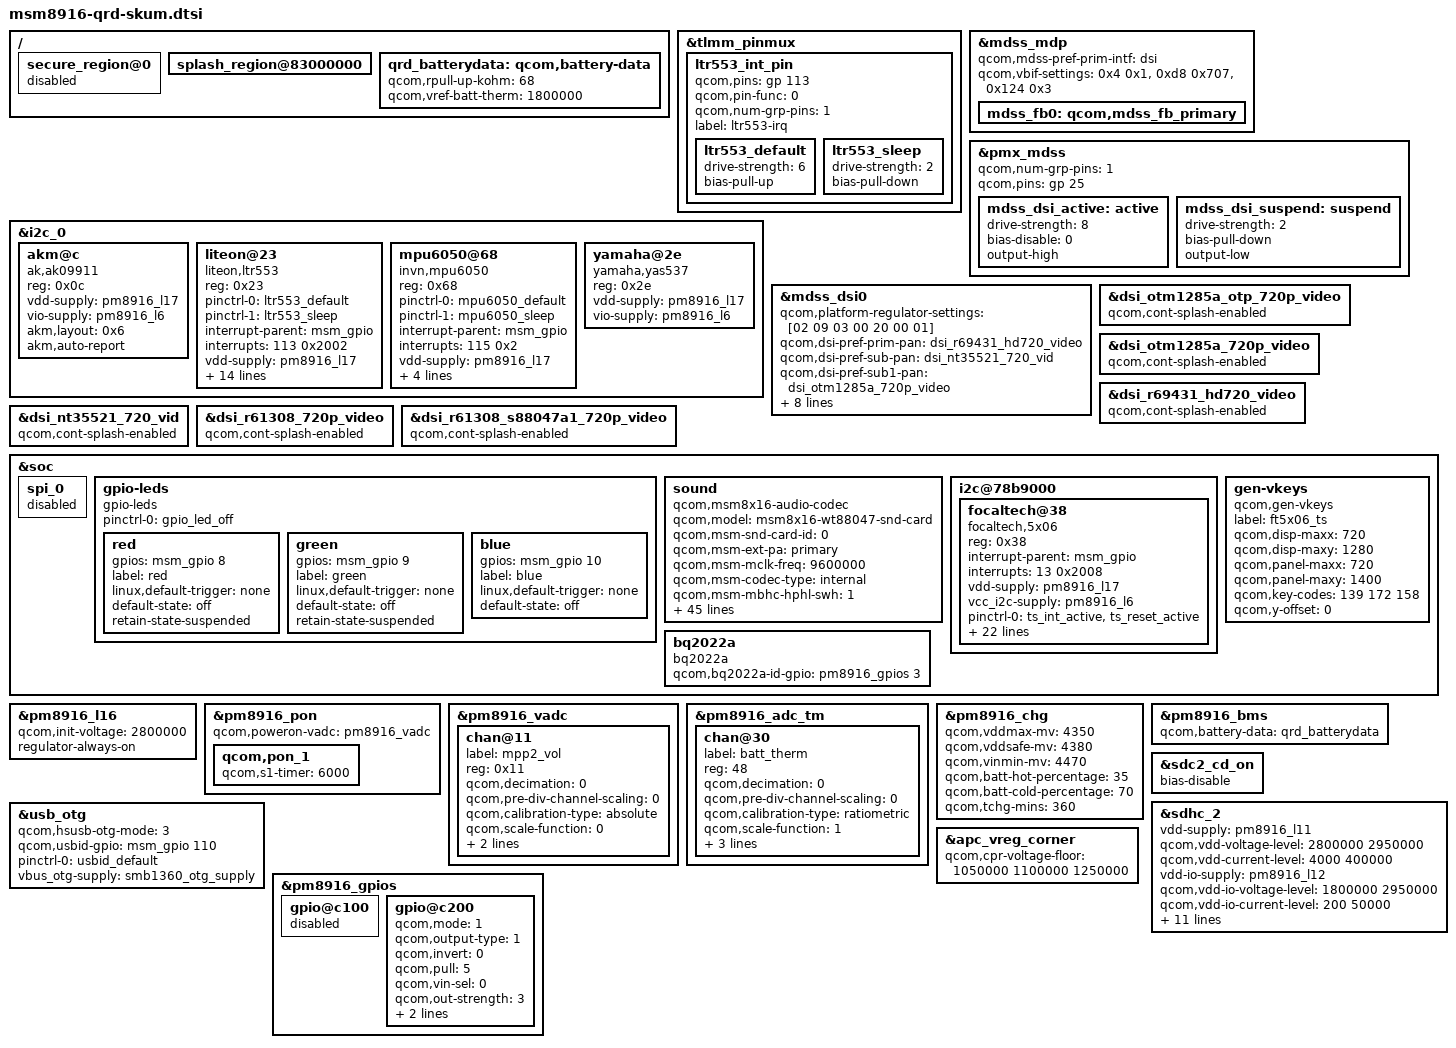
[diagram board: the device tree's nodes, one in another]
/* Copyright (c) 2014, The Linux Foundation. All rights reserved.
 *
 * This program is free software; you can redistribute it and/or modify
 * it under the terms of the GNU General Public License version 2 and
 * only version 2 as published by the Free Software Foundation.
 *
 * This program is distributed in the hope that it will be useful,
 * but WITHOUT ANY WARRANTY; without even the implied warranty of
 * MERCHANTABILITY or FITNESS FOR A PARTICULAR PURPOSE.  See the
 * GNU General Public License for more details.
 */

#include "msm8916-qrd.dtsi"
#include "msm8916-camera-sensor-qrd-skum.dtsi"
#include "dsi-panel-r69431-hd720-video.dtsi"
#include "dsi-panel-nt35521-720p-video.dtsi"
#include "dsi-panel-otm1285a-720p-video.dtsi"
#include "dsi-panel-r61308-720p-video.dtsi"
#include "dsi-panel-otm1285a-otp-720p-video.dtsi"
#include "dsi-panel-r61308-s88047a1-720p-video.dtsi"


/ {
        secure_region@0 {
	           status = "disabled";
	};
        splash_region@83000000 { /* Give this region to mdss_fb0 */
               /* status = "disabled"; */
	};
};

&tlmm_pinmux {
	ltr553_int_pin {
		qcom,pins = <&gp 113>;
		qcom,pin-func = <0>;
		qcom,num-grp-pins = <1>;
		label = "ltr553-irq";
		ltr553_default: ltr553_default {
			drive-strength = <6>;
			bias-pull-up;
		};
		ltr553_sleep: ltr553_sleep {
			drive-strength = <2>;
			bias-pull-down;
		};
	};
};

&i2c_0 { /* BLSP1 QUP2 */
	akm@c { /* Magnetic field sensor */
		compatible = "ak,ak09911";
		reg = <0x0c>;
		vdd-supply = <&pm8916_l17>;
		vio-supply = <&pm8916_l6>;
		akm,layout = <0x6>;
		akm,auto-report;
	};
	
	liteon@23 {
		compatible = "liteon,ltr553";
		reg = <0x23>;
		pinctrl-names = "default","sleep";
		pinctrl-0 = <&ltr553_default>;
		pinctrl-1 = <&ltr553_sleep>;
		interrupt-parent = <&msm_gpio>;
		interrupts = <113 0x2002>;
		vdd-supply = <&pm8916_l17>;
		vio-supply = <&pm8916_l6>;
		liteon,irq-gpio = <&msm_gpio 113 0x2002>;
		liteon,ps-threshold = <250>;
		liteon,ps-hysteresis-threshold = <150>;
		liteon,als-polling-time = <200>;
		liteon,als-ps-persist = <0>;
		liteon,ps-led = <0x7f>;
		liteon,ps-pulses = <4>;
		liteon,wakeup-threshold = <4>;
		liteon,als-integration-time = <0>;
		liteon,als-equation-0 = <1 1 7743 1059 600 1>;
		liteon,als-equation-1 = <4 1 2785 696 240 (-1)>;
		liteon,als-equation-2 = <0 0 5926 1300 44 1>;
		liteon,als-equation-3 = <0 0 0 0 1 1>;
	};

	mpu6050@68 {
		compatible = "invn,mpu6050";
		reg = <0x68>;
		pinctrl-names = "mpu_default","mpu_sleep";
		pinctrl-0 = <&mpu6050_default>;
		pinctrl-1 = <&mpu6050_sleep>;
		interrupt-parent = <&msm_gpio>;
		interrupts = <115 0x2>;
		vdd-supply = <&pm8916_l17>;	
		vlogic-supply = <&pm8916_l16>;
		vi2c-supply = <&pm8916_l6>;
		invn,gpio-int = <&msm_gpio 115 0x2>;
		invn,place = "Portrait Up Back Side";
	};

	yamaha@2e {
		compatible = "yamaha,yas537";
		reg = <0x2e>;
		vdd-supply = <&pm8916_l17>;
		vio-supply = <&pm8916_l6>;
	};
		
};

&mdss_mdp {
	qcom,mdss-pref-prim-intf = "dsi";
	qcom,vbif-settings = <0x4 0x1>, <0xd8 0x707>, <0x124 0x3>;

	mdss_fb0: qcom,mdss_fb_primary {
		/* Ketut P. Kumajaya: For old bootloader, old splash image */
		/* Both recovery and bootanimation framebuffer need this */
		/* qcom,memblock-reserve = <0x83200000 0xfa0000>;
		qcom,mdss-fb-splash-logo-enabled; */
	};
};

&pmx_mdss {
	qcom,num-grp-pins = <1>;
	qcom,pins = <&gp 25>;
	mdss_dsi_active: active {
		drive-strength = <8>; /* 8 mA */
		bias-disable = <0>; /* no pull */
		output-high;
	};
	mdss_dsi_suspend: suspend {
		drive-strength = <2>; /* 2 mA */
		bias-pull-down; /* pull down */
		output-low;
	};
};


&mdss_dsi0 {
	qcom,platform-regulator-settings = [02 09 03 00 20 00 01];
	qcom,dsi-pref-prim-pan = <&dsi_r69431_hd720_video>;
	qcom,dsi-pref-sub-pan = <&dsi_nt35521_720_vid>;
	qcom,dsi-pref-sub1-pan = <&dsi_otm1285a_720p_video>;
	qcom,dsi-pref-sub2-pan = <&dsi_r61308_720p_video>;
	qcom,dsi-pref-sub3-pan = <&dsi_otm1285a_otp_720p_video>;
	qcom,dsi-pref-sub4-pan = <&dsi_r61308_s88047a1_720p_video>;
	pinctrl-names = "mdss_default", "mdss_sleep";
	pinctrl-0 = <&mdss_dsi_active>;
	pinctrl-1 = <&mdss_dsi_suspend>;

	qcom,platform-reset-gpio = <&msm_gpio 25 0>;
};

&dsi_otm1285a_otp_720p_video {
    qcom,cont-splash-enabled;
};

&dsi_otm1285a_720p_video {
    qcom,cont-splash-enabled;
};

&dsi_r69431_hd720_video {
    qcom,cont-splash-enabled;
};

&dsi_nt35521_720_vid {
    qcom,cont-splash-enabled;
};

&dsi_r61308_720p_video {
    qcom,cont-splash-enabled;
};

&dsi_r61308_s88047a1_720p_video {
    qcom,cont-splash-enabled;
};



&soc {
	spi_0 {
		status = "disabled";
	};

	gpio-leds {
		compatible = "gpio-leds";
		status = "okay";
		pinctrl-names = "default";
		pinctrl-0 = <&gpio_led_off>;

		red {
			gpios = <&msm_gpio 8 0>;
			label = "red";
			linux,default-trigger = "none";
			default-state = "off";
			retain-state-suspended;
		};

		green {
			gpios = <&msm_gpio 9 0>;
			label = "green";
			linux,default-trigger = "none";
			default-state = "off";
			retain-state-suspended;
		};

		blue {
			gpios = <&msm_gpio 10 0>;
			label = "blue";
			linux,default-trigger = "none";
			default-state = "off";
		};
	};

	sound {
		compatible = "qcom,msm8x16-audio-codec";
		qcom,model = "msm8x16-wt88047-snd-card";
		qcom,msm-snd-card-id = <0>;
		qcom,msm-ext-pa = "primary";
		qcom,msm-mclk-freq = <9600000>;
		qcom,msm-codec-type = "internal";
		qcom,msm-mbhc-hphl-swh = <1>;
		qcom,msm-mbhc-gnd-swh = <0>;
		qcom,msm-hs-micbias-type = "internal";
		qcom,audio-routing =
			"RX_BIAS", "MCLK",
			"SPK_RX_BIAS", "MCLK",
			"INT_LDO_H", "MCLK",
			"MIC BIAS External", "Handset Mic",
			"MIC BIAS Internal2", "Headset Mic",
			"MIC BIAS External", "Secondary Mic",
			"AMIC1", "MIC BIAS External",
			"AMIC2", "MIC BIAS Internal2",
			"AMIC3", "MIC BIAS External";
		pinctrl-names = "cdc_lines_act",
				"cdc_lines_sus";
		pinctrl-0 = <&cdc_pdm_lines_act>;
		pinctrl-1 = <&cdc_pdm_lines_sus>;
		asoc-platform = <&pcm0>, <&pcm1>, <&voip>, <&voice>,
				<&loopback>, <&compress>, <&hostless>,
				<&afe>, <&lsm>, <&routing>, <&lpa>;
		asoc-platform-names = "msm-pcm-dsp.0", "msm-pcm-dsp.1",
				"msm-voip-dsp", "msm-pcm-voice", "msm-pcm-loopback",
				"msm-compress-dsp", "msm-pcm-hostless", "msm-pcm-afe",
				"msm-lsm-client", "msm-pcm-routing", "msm-pcm-lpa";
		asoc-cpu = <&dai_pri_auxpcm>, <&dai_hdmi>,
				<&dai_mi2s0>, <&dai_mi2s1>, <&dai_mi2s2>, <&dai_mi2s3>,
				<&sb_0_rx>, <&sb_0_tx>, <&sb_1_rx>, <&sb_1_tx>,
				<&sb_3_rx>, <&sb_3_tx>, <&sb_4_rx>, <&sb_4_tx>,
				<&bt_sco_rx>, <&bt_sco_tx>, <&bt_a2dp_rx>,
				<&int_fm_rx>, <&int_fm_tx>,
				<&afe_pcm_rx>, <&afe_pcm_tx>, <&afe_proxy_rx>, <&afe_proxy_tx>,
				<&incall_record_rx>, <&incall_record_tx>, <&incall_music_rx>,
				<&incall_music_2_rx>;
		asoc-cpu-names = "msm-dai-q6-auxpcm.1", "msm-dai-q6-hdmi.8",
				"msm-dai-q6-mi2s.0", "msm-dai-q6-mi2s.1",
				"msm-dai-q6-mi2s.2", "msm-dai-q6-mi2s.3",
				"msm-dai-q6-dev.16384", "msm-dai-q6-dev.16385",
				"msm-dai-q6-dev.16386", "msm-dai-q6-dev.16387",
				"msm-dai-q6-dev.16390", "msm-dai-q6-dev.16391",
				"msm-dai-q6-dev.16392", "msm-dai-q6-dev.16393",
				"msm-dai-q6-dev.12288", "msm-dai-q6-dev.12289",
				"msm-dai-q6-dev.12290", "msm-dai-q6-dev.12292",
				"msm-dai-q6-dev.12293",	"msm-dai-q6-dev.224",
				"msm-dai-q6-dev.225", "msm-dai-q6-dev.241",
				"msm-dai-q6-dev.240", "msm-dai-q6-dev.32771",
				"msm-dai-q6-dev.32772", "msm-dai-q6-dev.32773",
				"msm-dai-q6-dev.32770";
		asoc-codec = <&stub_codec>, <&pm8916_tombak_dig>;
		asoc-codec-names = "msm-stub-codec.1", "tombak_codec";
	};

	i2c@78b9000 { /* BLSP1 QUP5 */
		focaltech@38 {
			compatible = "focaltech,5x06";
			reg = <0x38>;
			interrupt-parent = <&msm_gpio>;
			interrupts = <13 0x2008>;
			vdd-supply = <&pm8916_l17>;
			vcc_i2c-supply = <&pm8916_l6>;
			/* pins used by touchscreen */
			pinctrl-names = "pmx_ts_active","pmx_ts_suspend";
			pinctrl-0 = <&ts_int_active &ts_reset_active>;
			pinctrl-1 = <&ts_int_suspend &ts_reset_suspend>;
			focaltech,name = "ft6436";
			focaltech,family-id = <0x36>;
			focaltech,reset-gpio = <&msm_gpio 12 0x0>;
			focaltech,irq-gpio = <&msm_gpio 13 0x2008>;
			focaltech,display-coords = <0 0 720 1280>;
			focaltech,panel-coords = <0 0 720 1280>;
			focaltech,button-map= <139 102 158>;
			focaltech,no-force-update;
			focaltech,i2c-pull-up;
			focaltech,group-id = <1>;
			focaltech,hard-reset-delay-ms = <20>;
			focaltech,soft-reset-delay-ms = <200>;
			focaltech,num-max-touches = <5>;
			focaltech,fw-delay-aa-ms = <30>;
			focaltech,fw-delay-55-ms = <30>;
			focaltech,fw-upgrade-id1 = <0x79>;
			focaltech,fw-upgrade-id2 = <0x18>;
			focaltech,fw-delay-readid-ms = <10>;
			focaltech,fw-delay-era-flsh-ms = <2000>;
			focaltech,fw-auto-cal;
			focaltech,ignore-id-check;
		};
	};


	gen-vkeys {
		compatible = "qcom,gen-vkeys";
		label = "ft5x06_ts";
		qcom,disp-maxx = <720>;
		qcom,disp-maxy = <1280>;
		qcom,panel-maxx = <720>;
		qcom,panel-maxy = <1400>;
		qcom,key-codes = <139 172 158>;
		qcom,y-offset = <0>;
	};

       bq2022a {
		compatible = "bq2022a";
		qcom,bq2022a-id-gpio = <&pm8916_gpios 3 0>;
		status= "okay";
	};

};

&pm8916_l16 {
	qcom,init-voltage = <2800000>;
	regulator-always-on;
};

&pm8916_pon {
	qcom,poweron-vadc = <&pm8916_vadc>;

	qcom,pon_1 {
		qcom,s1-timer = <6000>;
	};
};

&pm8916_vadc {
	chan@11 {
		label = "mpp2_vol";
		reg = <0x11>;
		qcom,decimation = <0>;
		qcom,pre-div-channel-scaling = <0>;
		qcom,calibration-type = "absolute";
		qcom,scale-function = <0>;
		qcom,hw-settle-time = <0>;
		qcom,fast-avg-setup = <0>;
	};
};

&pm8916_adc_tm {
	chan@30 {
		label = "batt_therm";
		reg = <48>;
		qcom,decimation = <0>;
		qcom,pre-div-channel-scaling = <0>;
		qcom,calibration-type = "ratiometric";
		qcom,scale-function = <1>;
		qcom,hw-settle-time = <11>;
		qcom,fast-avg-setup = <3>;
		qcom,btm-channel-number = <72>;
	};
};

&pm8916_chg {
	qcom,vddmax-mv = <4350>;
	qcom,vddsafe-mv = <4380>;
	qcom,vinmin-mv = <4470>;
	qcom,batt-hot-percentage = <35>;
	qcom,batt-cold-percentage = <70>;
	qcom,tchg-mins = <360>;
	status = "okay";
};

/ {
	qrd_batterydata: qcom,battery-data {
		qcom,rpull-up-kohm = <68>;
		qcom,vref-batt-therm = <1800000>;

		#include "batterydata-qrd-skuh-4v35-2000mah.dtsi"
	};
};

&pm8916_bms {
	status = "ok";
	qcom,battery-data = <&qrd_batterydata>;
};

&sdc2_cd_on {
	/delete-property/ bias-pull-up;
	bias-disable;
};

//mask sdhc2 config, push sdhc2 config to msm8916-ard-skul.dtsi
&sdhc_2 {
	vdd-supply = <&pm8916_l11>;
	qcom,vdd-voltage-level = <2800000 2950000>;
	qcom,vdd-current-level = <15000 400000>;

	vdd-io-supply = <&pm8916_l12>;
	qcom,vdd-io-voltage-level = <1800000 2950000>;
	qcom,vdd-io-current-level = <200 50000>;

	qcom,vdd-always-on;
	qcom,vdd-lpm-sup;
	qcom,vdd-current-level = <4000 400000>;

	pinctrl-names = "active", "sleep";
	pinctrl-0 = <&sdc2_clk_on &sdc2_cmd_on &sdc2_data_on >;
	pinctrl-1 = <&sdc2_clk_off &sdc2_cmd_off &sdc2_data_off>;

	#address-cells = <0>;
	interrupt-parent = <&sdhc_2>;
	interrupts = <0 1>;
	#interrupt-cells = <1>;
	interrupt-map-mask = <0xffffffff>;
	interrupt-map = <0 &intc 0 125 0
			1 &intc 0 221 0>;
	interrupt-names = "hc_irq", "pwr_irq", "status_irq";	

	qcom,nonremovable;
	status = "ok";
};

&usb_otg {
        qcom,hsusb-otg-mode = <3>;
        qcom,usbid-gpio = <&msm_gpio 110 0>;
        pinctrl-names = "default";
        pinctrl-0 = <&usbid_default>;
        vbus_otg-supply = <&smb1360_otg_supply>;
};

&pm8916_gpios {
	gpio@c100 { /* GPIO 2 */
		/* NFC_CLK_REQ */
		status = "disabled";
	};

	gpio@c200 { /* GPIO 3 */
		/* External regulator control for WTR */
		qcom,mode = <1>;
		qcom,output-type = <1>;
		qcom,invert = <0>;
		qcom,pull = <5>;
		qcom,vin-sel = <0>;
		qcom,out-strength = <3>;
		qcom,src-sel = <0>;
		qcom,master-en = <1>;
		status = "ok";
	};
};

&apc_vreg_corner {
	qcom,cpr-voltage-floor = <1050000 1100000 1250000>;
};
